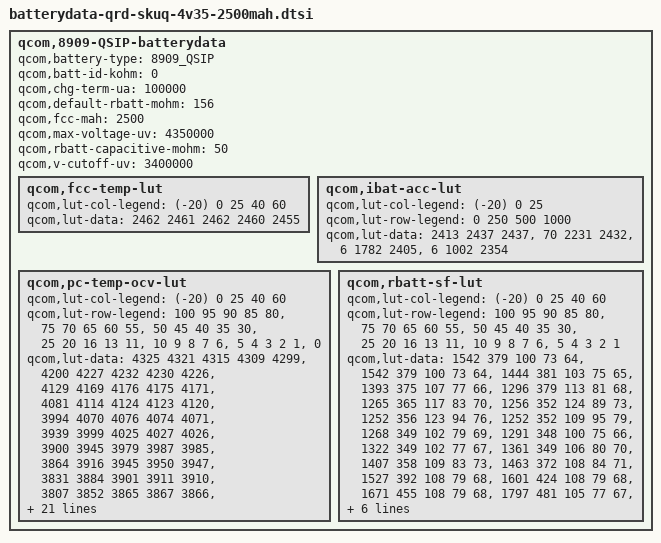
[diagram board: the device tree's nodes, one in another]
/* Copyright (c) 2016, The Linux Foundation. All rights reserved.
 *
 * This program is free software; you can redistribute it and/or modify
 * it under the terms of the GNU General Public License version 2 and
 * only version 2 as published by the Free Software Foundation.
 *
 * This program is distributed in the hope that it will be useful,
 * but WITHOUT ANY WARRANTY; without even the implied warranty of
 * MERCHANTABILITY or FITNESS FOR A PARTICULAR PURPOSE.  See the
 * GNU General Public License for more details.
*/

qcom,8909-QSIP-batterydata {
	qcom,battery-type = "8909_QSIP";
	qcom,batt-id-kohm = <0>;
	qcom,chg-term-ua = <100000>;
	qcom,default-rbatt-mohm = <156>;
	qcom,fcc-mah = <2500>;
	qcom,max-voltage-uv = <4350000>;
	qcom,rbatt-capacitive-mohm = <50>;
	qcom,v-cutoff-uv = <3400000>;

	qcom,fcc-temp-lut {
		qcom,lut-col-legend = <(-20) 0 25 40 60>;
		qcom,lut-data = <2462 2461 2462 2460 2455>;
	};

	qcom,ibat-acc-lut {
		qcom,lut-col-legend = <(-20) 0 25>;
		qcom,lut-row-legend = <0 250 500 1000>;
		qcom,lut-data = <2413 2437 2437>,
				<70 2231 2432>,
				<6 1782 2405>,
				<6 1002 2354>;
	};

	qcom,pc-temp-ocv-lut {
		qcom,lut-col-legend = <(-20) 0 25 40 60>;
		qcom,lut-row-legend = <100 95 90 85 80>,
					<75 70 65 60 55>,
					<50 45 40 35 30>,
					<25 20 16 13 11>,
					<10 9 8 7 6>,
					<5 4 3 2 1>,
					<0>;
		qcom,lut-data = <4325 4321 4315 4309 4299>,
				<4200 4227 4232 4230 4226>,
				<4129 4169 4176 4175 4171>,
				<4081 4114 4124 4123 4120>,
				<3994 4070 4076 4074 4071>,
				<3939 3999 4025 4027 4026>,
				<3900 3945 3979 3987 3985>,
				<3864 3916 3945 3950 3947>,
				<3831 3884 3901 3911 3910>,
				<3807 3852 3865 3867 3866>,
				<3787 3824 3837 3837 3836>,
				<3770 3798 3815 3815 3814>,
				<3754 3776 3797 3798 3796>,
				<3736 3762 3781 3783 3782>,
				<3719 3750 3766 3767 3762>,
				<3701 3740 3753 3748 3737>,
				<3679 3728 3736 3730 3716>,
				<3658 3717 3718 3711 3697>,
				<3638 3707 3701 3693 3680>,
				<3621 3699 3692 3683 3671>,
				<3612 3693 3690 3682 3670>,
				<3603 3687 3688 3680 3668>,
				<3591 3679 3685 3678 3667>,
				<3577 3670 3682 3676 3663>,
				<3560 3656 3675 3668 3651>,
				<3538 3634 3654 3644 3621>,
				<3509 3601 3613 3600 3574>,
				<3470 3552 3554 3541 3512>,
				<3412 3477 3472 3458 3425>,
				<3297 3341 3342 3328 3288>,
				<3000 3000 3000 3000 3000>;
	};

	qcom,rbatt-sf-lut {
		qcom,lut-col-legend = <(-20) 0 25 40 60>;
		qcom,lut-row-legend = <100 95 90 85 80>,
					<75 70 65 60 55>,
					<50 45 40 35 30>,
					<25 20 16 13 11>,
					<10 9 8 7 6>,
					<5 4 3 2 1>;
		qcom,lut-data = <1542 379 100 73 64>,
				<1542 379 100 73 64>,
				<1444 381 103 75 65>,
				<1393 375 107 77 66>,
				<1296 379 113 81 68>,
				<1265 365 117 83 70>,
				<1256 352 124 89 73>,
				<1252 356 123 94 76>,
				<1252 352 109 95 79>,
				<1268 349 102 79 69>,
				<1291 348 100 75 66>,
				<1322 349 102 77 67>,
				<1361 349 106 80 70>,
				<1407 358 109 83 73>,
				<1463 372 108 84 71>,
				<1527 392 108 79 68>,
				<1601 424 108 79 68>,
				<1671 455 108 79 68>,
				<1797 481 105 77 67>,
				<1905 496 104 76 66>,
				<1948 499 106 78 68>,
				<1841 472 109 80 70>,
				<1851 459 112 82 72>,
				<2015 473 117 85 74>,
				<2217 485 122 87 73>,
				<2488 498 119 84 69>,
				<2879 515 114 81 69>,
				<3471 542 115 83 71>,
				<4550 587 122 87 77>,
				<8603 724 163 125 153>;
	};
};
